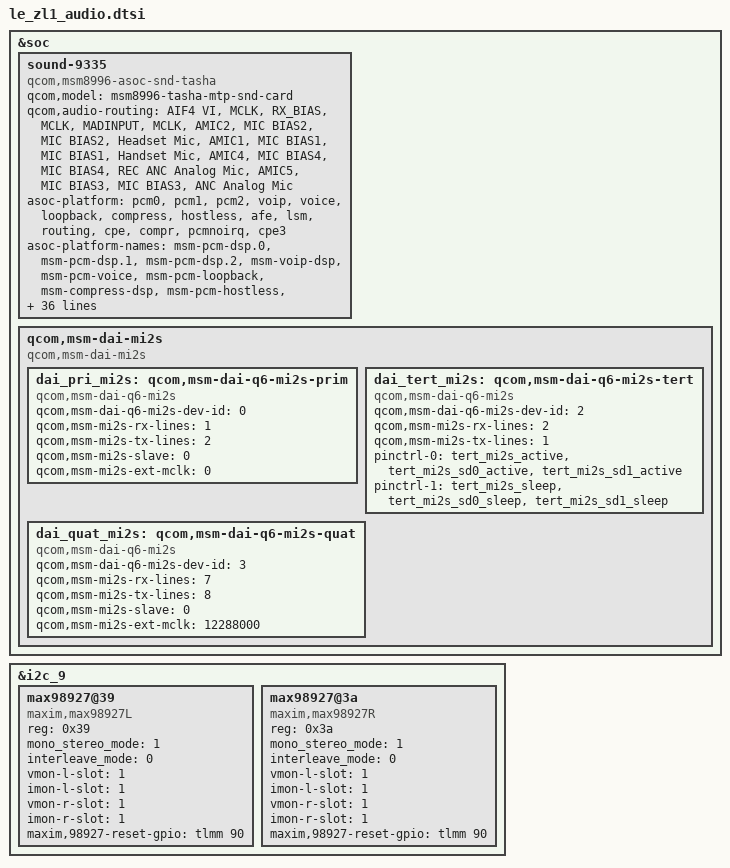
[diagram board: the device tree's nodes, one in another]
/* Copyright (c) 2014-2015, The Linux Foundation. All rights reserved.
 *
 * This program is free software; you can redistribute it and/or modify
 * it under the terms of the GNU General Public License version 2 and
 * only version 2 as published by the Free Software Foundation.
 *
 * This program is distributed in the hope that it will be useful,
 * but WITHOUT ANY WARRANTY; without even the implied warranty of
 * MERCHANTABILITY or FITNESS FOR A PARTICULAR PURPOSE.  See the
 * GNU General Public License for more details.
 */

&soc {
	sound-9335 {
		compatible = "qcom,msm8996-asoc-snd-tasha";
		qcom,model = "msm8996-tasha-mtp-snd-card";

		qcom,audio-routing =
			"AIF4 VI", "MCLK",
			"RX_BIAS", "MCLK",
			"MADINPUT", "MCLK",
			"AMIC2", "MIC BIAS2",
			"MIC BIAS2", "Headset Mic",
			"AMIC1", "MIC BIAS1",
			"MIC BIAS1", "Handset Mic",
			"AMIC4", "MIC BIAS4",
			"MIC BIAS4", "REC ANC Analog Mic",
			"AMIC5", "MIC BIAS3",
			"MIC BIAS3", "ANC Analog Mic";

		asoc-platform = <&pcm0>, <&pcm1>, <&pcm2>, <&voip>, <&voice>,
				<&loopback>, <&compress>, <&hostless>,
				<&afe>, <&lsm>, <&routing>, <&cpe>,
				<&compr>, <&pcmnoirq>, <&cpe3>;
		asoc-platform-names = "msm-pcm-dsp.0", "msm-pcm-dsp.1", "msm-pcm-dsp.2",
				"msm-voip-dsp", "msm-pcm-voice", "msm-pcm-loopback",
				"msm-compress-dsp", "msm-pcm-hostless", "msm-pcm-afe",
				"msm-lsm-client", "msm-pcm-routing", "msm-cpe-lsm",
				"msm-compr-dsp", "msm-pcm-dsp-noirq",
				"msm-cpe-lsm.3";
		asoc-cpu = <&dai_pri_auxpcm>, <&dai_sec_auxpcm>, <&dai_hdmi>,
				<&dai_pri_mi2s>,
				<&dai_tert_mi2s>, <&dai_quat_mi2s>,
				<&sb_0_rx>, <&sb_0_tx>, <&sb_1_rx>, <&sb_1_tx>,
				<&sb_2_rx>, <&sb_2_tx>, <&sb_3_rx>, <&sb_3_tx>,
				<&sb_4_rx>, <&sb_4_tx>, <&sb_5_tx>, <&afe_pcm_rx>,
				<&afe_pcm_tx>, <&afe_proxy_rx>, <&afe_proxy_tx>,
				<&incall_record_rx>, <&incall_record_tx>,
				<&incall_music_rx>, <&incall_music2_rx>,
				<&sb_5_rx>, <&sb_6_rx>;
		asoc-cpu-names = "msm-dai-q6-auxpcm.1", "msm-dai-q6-auxpcm.2",
				"msm-dai-q6-hdmi.8",
				"msm-dai-q6-mi2s.0",
				"msm-dai-q6-mi2s.2", "msm-dai-q6-mi2s.3",
				"msm-dai-q6-dev.16384", "msm-dai-q6-dev.16385",
				"msm-dai-q6-dev.16386", "msm-dai-q6-dev.16387",
				"msm-dai-q6-dev.16388", "msm-dai-q6-dev.16389",
				"msm-dai-q6-dev.16390", "msm-dai-q6-dev.16391",
				"msm-dai-q6-dev.16392", "msm-dai-q6-dev.16393",
				"msm-dai-q6-dev.16395", "msm-dai-q6-dev.224",
				"msm-dai-q6-dev.225", "msm-dai-q6-dev.241",
				"msm-dai-q6-dev.240", "msm-dai-q6-dev.32771",
				"msm-dai-q6-dev.32772", "msm-dai-q6-dev.32773",
				"msm-dai-q6-dev.32770", "msm-dai-q6-dev.16394",
                "msm-dai-q6-dev.16396";

		qcom,hdmi-audio-rx;
		/*letv,hifi-audio;*/
		/*letv,smartpa-audio;*/
		letv,smartpa-audio-max98927;
		letv,hph_irq_detect = <0>;
		asoc-codec = <&stub_codec>, <&hdmi_audio>;
		asoc-codec-names = "msm-stub-codec.1", "msm-hdmi-audio-codec-rx";
		/delete-property/ qcom,hph-en1-gpio;
		/delete-property/ qcom,hph-en0-gpio;
		qcom,us-euro-gpios = <&tlmm 21 0>;
		qcom,wsa-max-devs = <0>;
		qcom,wsa-devs = <0>;
		qcom,wsa-aux-dev-prefix = <0>;
	};

	qcom,msm-dai-mi2s {
		compatible = "qcom,msm-dai-mi2s";
		dai_pri_mi2s: qcom,msm-dai-q6-mi2s-prim {
			compatible = "qcom,msm-dai-q6-mi2s";
			qcom,msm-dai-q6-mi2s-dev-id = <0>;
			qcom,msm-mi2s-rx-lines = <1>; /* SD0 (1 << 0) */
			qcom,msm-mi2s-tx-lines = <2>; /* SD1 (1 << 1) */
			qcom,msm-mi2s-slave = <0>;
			qcom,msm-mi2s-ext-mclk = <0>;
			/*pinctrl-names = "default", "idle";
			pinctrl-0 = <&pri_mi2s_active &pri_mi2s_mclk_active &pri_mi2s_sd0_active &pri_mi2s_sd1_active>;
			pinctrl-1 = <&pri_mi2s_sleep &pri_mi2s_mclk_sleep &pri_mi2s_sd0_sleep &pri_mi2s_sd1_sleep>;*/
		};

		dai_tert_mi2s: qcom,msm-dai-q6-mi2s-tert {
			compatible = "qcom,msm-dai-q6-mi2s";
			qcom,msm-dai-q6-mi2s-dev-id = <2>;
			qcom,msm-mi2s-rx-lines = <2>;
			qcom,msm-mi2s-tx-lines = <1>;
			pinctrl-names = "default", "sleep";
			pinctrl-0 = <&tert_mi2s_active &tert_mi2s_sd0_active &tert_mi2s_sd1_active>;
			pinctrl-1 = <&tert_mi2s_sleep &tert_mi2s_sd0_sleep &tert_mi2s_sd1_sleep>;
		};

		dai_quat_mi2s: qcom,msm-dai-q6-mi2s-quat {
			compatible = "qcom,msm-dai-q6-mi2s";
			qcom,msm-dai-q6-mi2s-dev-id = <3>;
			qcom,msm-mi2s-rx-lines = <7>; /* SD0 (1 << 0) | SD1 (1 << 1) | SD2 (1 << 2) */
			qcom,msm-mi2s-tx-lines = <8>; /* SD2 (1 << 3) */
			qcom,msm-mi2s-slave = <0>;
			qcom,msm-mi2s-ext-mclk = <12288000>;
			/*pinctrl-names = "default", "idle";
			pinctrl-0 = <&quat_mi2s_active &quat_mi2s_mclk_active &quat_mi2s_sd0_active &quat_mi2s_sd1_active &quat_mi2s_sd2_active &quat_mi2s_sd3_active>;
			pinctrl-1 = <&quat_mi2s_sleep &quat_mi2s_mclk_sleep &quat_mi2s_sd0_sleep &quat_mi2s_sd1_sleep &quat_mi2s_sd2_sleep &quat_mi2s_sd3_sleep>;*/
		};
	};
};

&i2c_9 {
	max98927@39 {/* max98927 smartpa device*/
		compatible = "maxim,max98927L";
		reg = <0x39>;
		mono_stereo_mode = <1>;
		interleave_mode = <0>;
		vmon-l-slot = <1>;
		imon-l-slot = <1>;
		vmon-r-slot = <1>;
		imon-r-slot = <1>;
		maxim,98927-reset-gpio = <&tlmm 90 0>;
	};
	max98927@3a {
		compatible = "maxim,max98927R";
		reg = <0x3a>;
		mono_stereo_mode = <1>;
		interleave_mode = <0>;
		vmon-l-slot = <1>;
		imon-l-slot = <1>;
		vmon-r-slot = <1>;
		imon-r-slot = <1>;
		maxim,98927-reset-gpio = <&tlmm 90 0>;
	};
};
